# tle984x register map
Vendor: Infineon; File version: 1.9.5
CPU: CM0 r2p1, little endian, no MPU, no FPU, 2 interrupt priority bits
Registers are 32-bit, read-write, reset 0x0 unless marked. A register's access mark holds for its fields unless they carry their own. Offsets are from the block's base; [hi:lo] are bit positions; {n}, {i} and the like mark numbered series; 'fields as' and 'values as' point back to an identical list.

## ADC2 — Measurement core module (incl. ADC2) registers
Base 0x4801C000
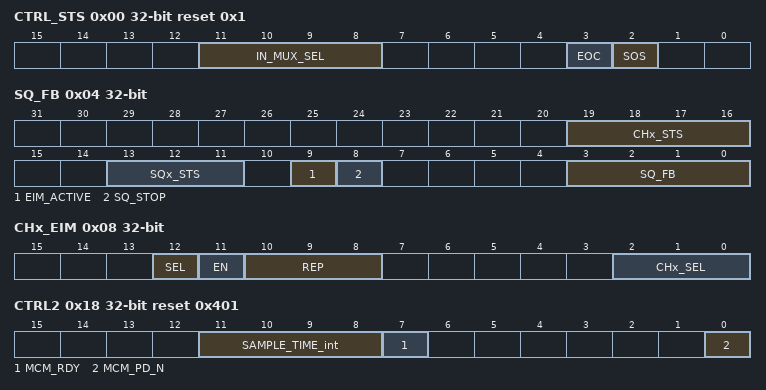
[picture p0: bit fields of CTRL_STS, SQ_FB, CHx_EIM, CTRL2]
0x00 CTRL_STS reset 0x1 — ADC2 control and status register
  [11:8] IN_MUX_SEL — Channel for software mode
    {v}=CH{v}_EN (Channel {v} enable) (v=0..6)
  [3] EOC ro — ADC2 end of conversion (software mode)
    0=PENDING (Conversion still running); 1=FINISHED (Conversion has finished)
  [2] SOS — ADC2 start of sampling/conversion (software mode)
    0=DISABLE (No conversion is started); 1=ENABLE (Conversion is started)
0x04 SQ_FB ro (reset mask 0xFF0000F0) — Sequencer feedback register
  [19:16] CHx_STS — Current ADC2 channel
    {v}=CH{v} (Channel {v} enable) (v=0..6)
  [13:11] SQx_STS — Current active ADC2 sequence
    {v}=SQ{v+1} (Sequence {v+1} enable) (v=0..6)
  [9] EIM_ACTIVE — ADC2 EIM active
    0=NOT_ACTIVE (EIM not active); 1=ACTIVE (EIM active)
  [8] SQ_STOP — ADC2 sequencer stop signal for DPP
    0=DPP_RUNNING (Post processing sequencer in running mode); 1=DPP_STOPPED (Post processing sequencer stopped/software mode entered)
  [3:0] SQ_FB — Current sequence that caused software mode
    {v}=SQ{v+1} (Sequence {v+1}) (v=0..6); 11=CH_MASK (Channel mask = 0); 12=SUSPEND (Debug suspend mode)
0x08 CHx_EIM — Channel settings bits for exceptional interrupt measurement register
  [12] SEL — Exceptional interrupt measurement (EIM) trigger select
    0=TRIGGERS (GPT12PISEL.T3_GPT12_SEL, GPT12_PISEL triggers EIM); 1=NOT_SUPPORTED
  [11] EN — Exceptional interrupt measurement (EIM) trigger event enable
    0=DISABLE (Start of EIM disabled); 1=ENABLE (Start of EIM enabled)
  [10:8] REP — Repeat count for exceptional interrupt measurement (EIM)
    0=1 measurement; 1=2 measurements; 2=4 measurements; 3=8 measurements; 4=16 measurements; 5=32 measurements; 6=64 measurements; 7=128 measurements
  [2:0] CHx_SEL — Channel set for exceptional interrupt measurement (EIM)
    {v}=CH{v}_EN (Channel {v} enable) (v=0..6)
0x10 MAX_TIME — Maximum time for software mode register
  [7:0] MAX_TIME — Maximum time in software mode
    0=MIN (Software mode is immediately left); 255=MAX (Software mode is active for 12.75 us)
0x14 CTRL1 — Measurement unit control 1 register
  [6:0] CALIB_EN_6_0 — Calibration enable for channels 6 to 0
    1=CH0_EN (Channel 0 calibration enable); 2=CH1_EN (Channel 1 calibration enable); 4=CH2_EN (Channel 2 calibration enable); 8=CH3_EN (Channel 3 calibration enable); 16=CH4_EN (Channel 4 calibration enable); 32=CH5_EN (Channel 5 calibration enable); 64=CH6_EN (Channel 6 calibration enable)
0x18 CTRL2 reset 0x401 — Measurement unit control 2 register
  [11:8] SAMPLE_TIME_int — Sample time of ADC2
    0=MICLK4 (4 MI_CLK clock periods); 1=MICLK6 (6 MI_CLK clock periods); 2=MICLK8 (8 MI_CLK clock periods); 3=MICLK10 (10 MI_CLK clock periods); 4=MICLK12 (12 MI_CLK clock periods (default)); 5=MICLK14 (14 MI_CLK clock periods); 6=MICLK16 (16 MI_CLK clock periods); 7=MICLK18 (18 MI_CLK clock periods); 8=MICLK20 (20 MI_CLK clock periods); 9=MICLK22 (22 MI_CLK clock periods)
  [7] MCM_RDY ro — Ready signal for MCM
    0=NOT_READY (Measurement core module in start-up phase); 1=READY (Measurement core module start-up phase finished)
  [0] MCM_PD_N — Power down signal for MCM
    0=DISABLED (Measurement core module disabled); 1=ENABLED (Measurement core module enabled)
0x1C CTRL4 reset 0x7F — Measurement unit control 4 register
  [6:0] FILT_OUT_SEL_6_0 — Output filter selection for channels 0 to 6
    0=UNFILTERED (ADC2 unfiltered data can be monitored in the corresponding ADC2_FILT_OUTx registers); 1=CH_0 (Channel 0 IIR data enabled for ADC2_FILT_OUT0 register); 2=CH_1 (Channel 1 IIR data enabled for ADC2_FILT_OUT1 register); 4=CH_2 (Channel 2 IIR data enabled for ADC2_FILT_OUT2 register); 8=CH_3 (Channel 3 IIR data enabled for ADC2_FILT_OUT3 register); 16=CH_4 (Channel 4 IIR data enabled for ADC2_FILT_OUT4 register); 32=CH_5 (Channel 5 IIR data enabled for ADC2_FILT_OUT5 register); 64=CH_6 (Channel 6 IIR data enabled for ADC2_FILT_OUT6 register); 127=ALL (For channels 6-0 IIR data is enabled for ADC2_FILT_OUTx registers)
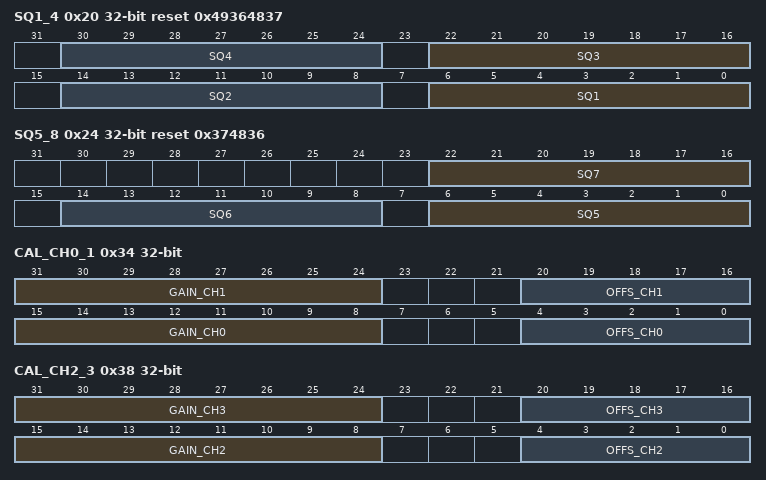
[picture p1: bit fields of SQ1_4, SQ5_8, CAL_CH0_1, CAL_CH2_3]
0x20 SQ1_4 reset 0x49364837 — Measurement channel enable bits for cycle 1-4 register
  [all] fields
    1=CH0_EN (Channel 0 enable); 2=CH1_EN (Channel 1 enable); 4=CH2_EN (Channel 2 enable); 8=CH3_EN (Channel 3 enable); 16=CH4_EN (Channel 4 enable); 32=CH5_EN (Channel 5 enable); 64=CH6_EN (Channel 6 enable)
  [8n-2:8n-8] SQ{n} (n=1..4) — Sequence {n} channel enable
0x24 SQ5_8 reset 0x374836 — Measurement channel enable bits for cycle 5-8 register
  [all] fields
    values as the fields of SQ1_4
  [22:16] SQ7 — Sequence 7 channel enable
  [14:8] SQ6 — Sequence 6 channel enable
  [6:0] SQ5 — Sequence 5 channel enable
0x34 CAL_CH0_1 — Calibration for channel 0 and 1 register
  [31:24] GAIN_CH1 — Gain calibration for channel 1
  [20:16] OFFS_CH1 ro — Offset calibration for channel 1
  [15:8] GAIN_CH0 ro — Gain calibration for channel 0
  [4:0] OFFS_CH0 — Offset calibration for channel 0
0x38 CAL_CH2_3 — Calibration for channel 2 and 3 register
  [31:24] GAIN_CH3 — Gain calibration for channel 3
  [20:16] OFFS_CH3 — Offset calibration for channel 3
  [15:8] GAIN_CH2 — Gain calibration for channel 2
  [4:0] OFFS_CH2 — Offset calibration for channel 2
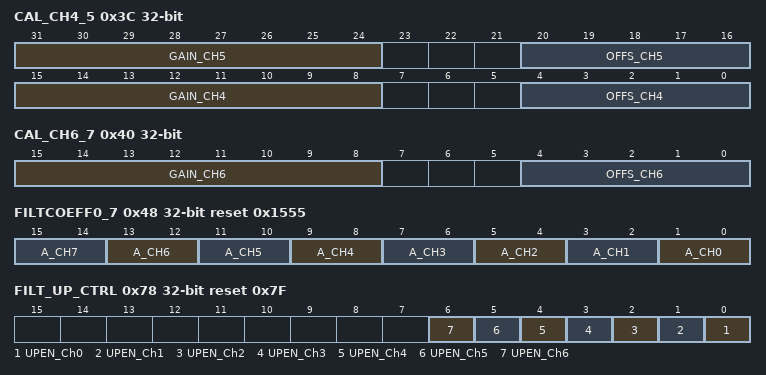
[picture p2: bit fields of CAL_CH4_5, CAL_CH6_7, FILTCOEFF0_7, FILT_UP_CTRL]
0x3C CAL_CH4_5 — Calibration for channel 4 and 5 register
  [31:24] GAIN_CH5 — Gain calibration for channel 5
  [20:16] OFFS_CH5 — Offset calibration for channel 5
  [15:8] GAIN_CH4 — Gain calibration for channel 4
  [4:0] OFFS_CH4 — Offset calibration for channel 4
0x40 CAL_CH6_7 — Calibration for channel 6 and 7 register
  [15:8] GAIN_CH6 — Gain calibration for channel 6
  [4:0] OFFS_CH6 — Offset calibration for channel 6
0x48 FILTCOEFF0_7 reset 0x1555 — Filter coefficients ADC channel 0-7 register
  [all] fields
    0=1_2 (1/2 weight of current sample); 1=1_4 (1/4 weight of current sample); 2=1_8 (1/8 weight of current sample); 3=1/16 weight of current sample
  [2n+1:2n] A_CH{n} (n=0..7) — Filter coefficient A for ADC channel {n}
{0x50+4i} FILT_OUT{i} ro (reset mask 0xFFFFF000) (i=0..6) — ADC or filter output channel {i} register
  [9:0] OUT_CH{i} — ADC or filter output value channel {i}
0x78 FILT_UP_CTRL reset 0x7F — Upper threshold filter enable register
  [all] fields
    0=DISABLE; 1=ENABLE
  [n] UPEN_Ch{n} (n=0..6) — Upper threshold IIR filter enable ch {n}
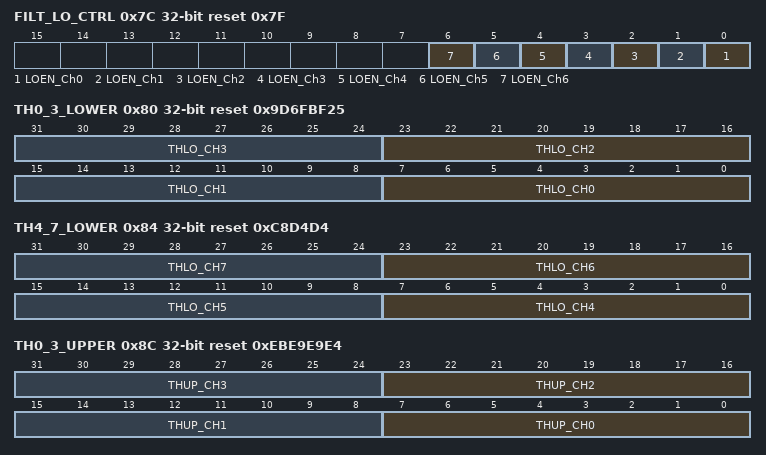
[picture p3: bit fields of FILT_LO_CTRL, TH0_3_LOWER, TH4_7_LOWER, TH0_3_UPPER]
0x7C FILT_LO_CTRL reset 0x7F — Lower threshold filter enable register
  [all] fields
    0=DISABLE; 1=ENABLE
  [n] LOEN_Ch{n} (n=0..6) — Lower threshold IIR filter enable ch {n}
0x80 TH0_3_LOWER reset 0x9D6FBF25 — Lower comparator trigger level channel 0-3 register
  [all] fields
    0=MIN (Min. threshold value); 255=MAX (Max. threshold value)
  [8n+7:8n] THLO_CH{n} (n=0..3) — Channel {n} lower trigger level
0x84 TH4_7_LOWER reset 0xC8D4D4 — Lower comparator trigger level channel 4-7 register
  [all] fields
    0=MIN (Min. threshold value); 255=MAX (Max. threshold value)
  [8n-25:8n-32] THLO_CH{n} (n=4..7) — Channel {n} lower trigger level
0x8C TH0_3_UPPER reset 0xEBE9E9E4 — Upper comparator trigger level channel 0-3 register
  [all] fields
    0=MIN (Min. threshold value = 0); 255=MAX (Max. threshold value = 255)
  [8n+7:8n] THUP_CH{n} (n=0..3) — Channel {n} upper trigger level
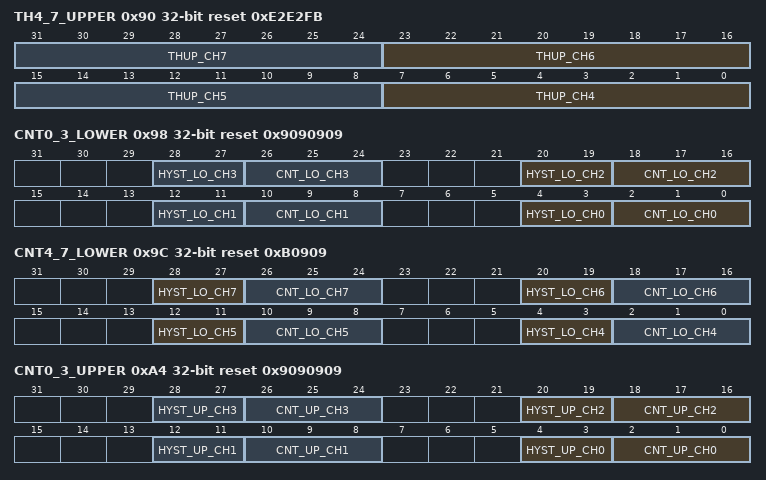
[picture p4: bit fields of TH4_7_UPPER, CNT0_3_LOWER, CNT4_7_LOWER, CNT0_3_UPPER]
0x90 TH4_7_UPPER reset 0xE2E2FB — Upper comparator trigger level channel 4-7 register
  [all] fields
    values as the fields of TH0_3_UPPER
  [8n-25:8n-32] THUP_CH{n} (n=4..7) — Channel {n} upper trigger level
0x98 CNT0_3_LOWER reset 0x9090909 — Lower counter trigger level channel 0-3 register
  [8n+4:8n+3] HYST_LO_CH{n} (n=0..3) — Channel {n} lower hysteresis
    0=HYSTOFF (Hysteresis switched off); 1=HYST4 (Hysteresis = 4); 2=HYST8 (Hysteresis = 8); 3=HYST16 (Hysteresis = 16)
  [8n+2:8n] CNT_LO_CH{n} (n=0..3) — Lower timer trigger threshold channel {n}
    0=1 measurement; 1=2 measurements; 2=4 measurements; 3=8 measurements; 4=16 measurements; 5=32 measurements; 6=63 measurements; 7=63 measurements
0x9C CNT4_7_LOWER reset 0xB0909 — Lower counter trigger level channel 4-7 register
  [28:27] HYST_LO_CH7 — Channel 6 lower hysteresis
    values as CNT0_3_LOWER.HYST_LO_CH0
  [26:24] CNT_LO_CH7 — Lower timer trigger threshold channel 6
    values as CNT0_3_LOWER.CNT_LO_CH0
  [20:19] HYST_LO_CH6 — Channel 6 lower hysteresis
    values as CNT0_3_LOWER.HYST_LO_CH0
  [18:16] CNT_LO_CH6 — Lower timer trigger threshold channel 6
    values as CNT0_3_LOWER.CNT_LO_CH0
  [12:11] HYST_LO_CH5 — Channel 5 lower hysteresis
    values as CNT0_3_LOWER.HYST_LO_CH0
  [10:8] CNT_LO_CH5 — Lower timer trigger threshold channel 5
    values as CNT0_3_LOWER.CNT_LO_CH0
  [4:3] HYST_LO_CH4 — Channel 4 lower hysteresis
    values as CNT0_3_LOWER.HYST_LO_CH0
  [2:0] CNT_LO_CH4 — Lower timer trigger threshold channel 4
    values as CNT0_3_LOWER.CNT_LO_CH0
0xA4 CNT0_3_UPPER reset 0x9090909 — Upper counter trigger level channel 0-3 register
  [8n+4:8n+3] HYST_UP_CH{n} (n=0..3) — Channel {n} upper hysteresis
    values as CNT0_3_LOWER.HYST_LO_CH0
  [8n+2:8n] CNT_UP_CH{n} (n=0..3) — Upper timer trigger threshold channel {n}
    values as CNT0_3_LOWER.CNT_LO_CH0
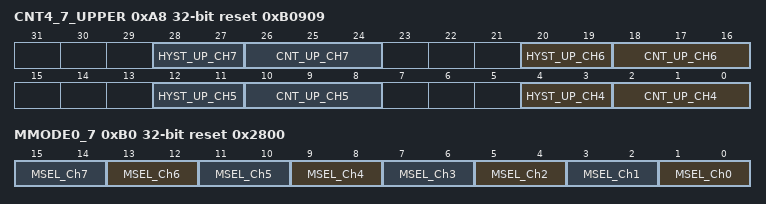
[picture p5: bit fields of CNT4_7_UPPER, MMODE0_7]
0xA8 CNT4_7_UPPER reset 0xB0909 — Upper counter trigger level channel 4-7 register
  [8n-28:8n-29] HYST_UP_CH{n} (n=4..7) — Channel {n} upper hysteresis
    values as CNT0_3_LOWER.HYST_LO_CH0
  [8n-30:8n-32] CNT_UP_CH{n} (n=4..7) — Upper timer trigger threshold channel {n}
    values as CNT0_3_LOWER.CNT_LO_CH0
0xB0 MMODE0_7 reset 0x2800 — Overvoltage measurement mode of channel 0-7 register
  [all] fields
    0=MMODE0 (Upper & lower voltage/limit measurement); 1=MMODEUV (Undervoltage/-limit measurement); 2=MMODEOV (Overvoltage/-limit measurement)
  [2n+1:2n] MSEL_Ch{n} (n=0..7) — Measurement mode ch {n}
0xBC STATUS ro — ADC2 HV status register
  [1] READY — HVADC ready bit
    0=NOT_READY (Module in power down or in init phase); 1=READY (Set automatically 5 ADC clock cycles after module is enabled)
